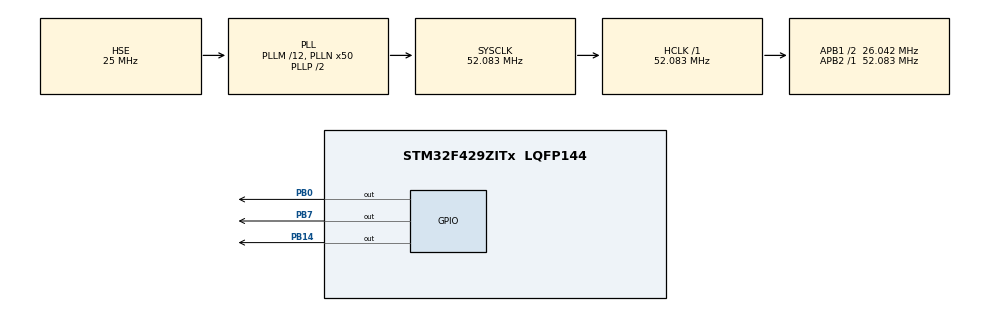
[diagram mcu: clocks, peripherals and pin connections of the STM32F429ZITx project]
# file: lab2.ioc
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FREERTOS.Tasks01=defaultTask,24,128,StartDefaultTask,Default,NULL,Dynamic,NULL,NULL;LED1,8,128,StartTask02,Default,NULL,Dynamic,NULL,NULL;LED2,8,128,StartTask03,Default,NULL,Dynamic,NULL,NULL;LED3,8,128,StartTask04,Default,NULL,Dynamic,NULL,NULL
Mcu.Family=STM32F4
Mcu.Name=STM32F429ZITx
Mcu.Package=LQFP144
NVIC.PriorityGroup=NVIC_PRIORITYGROUP_4
NVIC.TIM1_UP_TIM10_IRQn=true\:0\:0\:false\:false\:true\:false\:false\:true
NVIC.TimeBase=TIM1_UP_TIM10_IRQn
NVIC.TimeBaseIP=TIM1
PB0.Signal=GPIO_Output
PB14.Signal=GPIO_Output
PB7.Signal=GPIO_Output
PH0/OSC_IN.Mode=HSE-External-Oscillator
PH0/OSC_IN.Signal=RCC_OSC_IN
PH1/OSC_OUT.Mode=HSE-External-Oscillator
PH1/OSC_OUT.Signal=RCC_OSC_OUT
ProjectManager.HeapSize=0x200
ProjectManager.StackSize=0x400
ProjectManager.TargetToolchain=STM32CubeIDE
RCC.48MHZClocksFreq_Value=26041666.666666664
RCC.AHBFreq_Value=52083333.33333333
RCC.APB1CLKDivider=RCC_HCLK_DIV2
RCC.APB1Freq_Value=26041666.666666664
RCC.APB1TimFreq_Value=52083333.33333333
RCC.APB2Freq_Value=52083333.33333333
RCC.APB2TimFreq_Value=52083333.33333333
RCC.CortexFreq_Value=52083333.33333333
RCC.HCLKFreq_Value=52083333.33333333
RCC.HSE_VALUE=25000000
RCC.HSI_VALUE=16000000
RCC.LSE_VALUE=32768
RCC.PLLM=12
RCC.PLLN=50
RCC.PLLSourceVirtual=RCC_PLLSOURCE_HSE
RCC.SYSCLKFreq_VALUE=52083333.33333333
RCC.SYSCLKSource=RCC_SYSCLKSOURCE_PLLCLK
RCC.VCOOutputFreq_Value=104166666.66666666
VP_FREERTOS_VS_CMSIS_V2.Mode=CMSIS_V2
VP_SYS_VS_tim1.Mode=TIM1
board=custom

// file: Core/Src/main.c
/* USER CODE BEGIN Header */
/**
  ******************************************************************************
  * @file           : main.c
  * @brief          : Main program body
  ******************************************************************************
  * @attention
  *
  * <h2><center>&copy; Copyright (c) 2020 STMicroelectronics.
  * All rights reserved.</center></h2>
  *
  * This software component is licensed by ST under BSD 3-Clause license,
  * the "License"; You may not use this file except in compliance with the
  * License. You may obtain a copy of the License at:
  *                        opensource.org/licenses/BSD-3-Clause
  *
  ******************************************************************************
  */
/* USER CODE END Header */

#include "main.h"
#include "cmsis_os.h"

/* Definitions for defaultTask */
osThreadId_t defaultTaskHandle;
const osThreadAttr_t defaultTask_attributes = {
  .name = "defaultTask",
  .priority = (osPriority_t) osPriorityNormal,
  .stack_size = 128 * 4
};
/* Definitions for LED1 */
osThreadId_t LED1Handle;
const osThreadAttr_t LED1_attributes = {
  .name = "LED1",
  .priority = (osPriority_t) osPriorityLow,
  .stack_size = 128 * 4
};
/* Definitions for LED2 */
osThreadId_t LED2Handle;
const osThreadAttr_t LED2_attributes = {
  .name = "LED2",
  .priority = (osPriority_t) osPriorityLow,
  .stack_size = 128 * 4
};
/* Definitions for LED3 */
osThreadId_t LED3Handle;
const osThreadAttr_t LED3_attributes = {
  .name = "LED3",
  .priority = (osPriority_t) osPriorityLow,
  .stack_size = 128 * 4
};

void SystemClock_Config(void);
static void MX_GPIO_Init(void);
void StartDefaultTask(void *argument);
void StartTask02(void *argument);
void StartTask03(void *argument);
void StartTask04(void *argument);

int main(void)
{

  /* MCU Configuration--------------------------------------------------------*/

  /* Reset of all peripherals, Initializes the Flash interface and the Systick. */
  HAL_Init();

  /* Configure the system clock */
  SystemClock_Config();

  /* Initialize all configured peripherals */
  MX_GPIO_Init();

  /* Init scheduler */
  osKernelInitialize();

  /* Create the thread(s) */
  /* creation of defaultTask */
  defaultTaskHandle = osThreadNew(StartDefaultTask, NULL, &defaultTask_attributes);

  /* creation of LED1 */
  LED1Handle = osThreadNew(StartTask02, NULL, &LED1_attributes);

  /* creation of LED2 */
  LED2Handle = osThreadNew(StartTask03, NULL, &LED2_attributes);

  /* creation of LED3 */
  LED3Handle = osThreadNew(StartTask04, NULL, &LED3_attributes);

  /* Start scheduler */
  osKernelStart();

  /* We should never get here as control is now taken by the scheduler */
  /* Infinite loop */
  while (1)
  {

  }
}

void SystemClock_Config(void)
{
  RCC_OscInitTypeDef RCC_OscInitStruct = {0};
  RCC_ClkInitTypeDef RCC_ClkInitStruct = {0};

  /** Configure the main internal regulator output voltage
  */
  __HAL_RCC_PWR_CLK_ENABLE();
  __HAL_PWR_VOLTAGESCALING_CONFIG(PWR_REGULATOR_VOLTAGE_SCALE3);
  /** Initializes the CPU, AHB and APB busses clocks
  */
  RCC_OscInitStruct.OscillatorType = RCC_OSCILLATORTYPE_HSE;
  RCC_OscInitStruct.HSEState = RCC_HSE_ON;
  RCC_OscInitStruct.PLL.PLLState = RCC_PLL_ON;
  RCC_OscInitStruct.PLL.PLLSource = RCC_PLLSOURCE_HSE;
  RCC_OscInitStruct.PLL.PLLM = 12;
  RCC_OscInitStruct.PLL.PLLN = 50;
  RCC_OscInitStruct.PLL.PLLP = RCC_PLLP_DIV2;
  RCC_OscInitStruct.PLL.PLLQ = 4;
  if (HAL_RCC_OscConfig(&RCC_OscInitStruct) != HAL_OK)
  {
    Error_Handler();
  }
  /** Initializes the CPU, AHB and APB busses clocks
  */
  RCC_ClkInitStruct.ClockType = RCC_CLOCKTYPE_HCLK|RCC_CLOCKTYPE_SYSCLK
                              |RCC_CLOCKTYPE_PCLK1|RCC_CLOCKTYPE_PCLK2;
  RCC_ClkInitStruct.SYSCLKSource = RCC_SYSCLKSOURCE_PLLCLK;
  RCC_ClkInitStruct.AHBCLKDivider = RCC_SYSCLK_DIV1;
  RCC_ClkInitStruct.APB1CLKDivider = RCC_HCLK_DIV2;
  RCC_ClkInitStruct.APB2CLKDivider = RCC_HCLK_DIV1;

  if (HAL_RCC_ClockConfig(&RCC_ClkInitStruct, FLASH_LATENCY_1) != HAL_OK)
  {
    Error_Handler();
  }
}

static void MX_GPIO_Init(void)
{
  GPIO_InitTypeDef GPIO_InitStruct = {0};

  /* GPIO Ports Clock Enable */
  __HAL_RCC_GPIOH_CLK_ENABLE();
  __HAL_RCC_GPIOB_CLK_ENABLE();

  /*Configure GPIO pin Output Level */
  HAL_GPIO_WritePin(GPIOB, GPIO_PIN_0|GPIO_PIN_14|GPIO_PIN_7, GPIO_PIN_RESET);

  /*Configure GPIO pins : PB0 PB14 PB7 */
  GPIO_InitStruct.Pin = GPIO_PIN_0|GPIO_PIN_14|GPIO_PIN_7;
  GPIO_InitStruct.Mode = GPIO_MODE_OUTPUT_PP;
  GPIO_InitStruct.Pull = GPIO_NOPULL;
  GPIO_InitStruct.Speed = GPIO_SPEED_FREQ_LOW;
  HAL_GPIO_Init(GPIOB, &GPIO_InitStruct);

}

void StartDefaultTask(void *argument)
{
  for(;;)
  {
    osDelay(1);
  }
}

void StartTask02(void *argument)
{
  /* USER CODE BEGIN StartTask02 */
  /* Infinite loop */
  for(;;)
  {
	  HAL_GPIO_TogglePin(GPIOB, GPIO_PIN_0);
	  HAL_Delay(250);
//    osDelay(1);
  }
  /* USER CODE END StartTask02 */
}

void StartTask03(void *argument)
{
  /* USER CODE BEGIN StartTask03 */
  /* Infinite loop */
  for(;;)
  {
	  HAL_GPIO_TogglePin(GPIOB, GPIO_PIN_7);
	  HAL_Delay(500);
//    osDelay(1);
  }
  /* USER CODE END StartTask03 */
}

void StartTask04(void *argument)
{
  /* USER CODE BEGIN StartTask04 */
  /* Infinite loop */
  for(;;)
  {
	  HAL_GPIO_TogglePin(GPIOB, GPIO_PIN_14);
	  HAL_Delay(750);
//    osDelay(1);
  }
  /* USER CODE END StartTask04 */
}

 /**
  * @brief  Period elapsed callback in non blocking mode
  * @note   This function is called  when TIM1 interrupt took place, inside
  * HAL_TIM_IRQHandler(). It makes a direct call to HAL_IncTick() to increment
  * a global variable "uwTick" used as application time base.
  * @param  htim : TIM handle
  * @retval None
  */
void HAL_TIM_PeriodElapsedCallback(TIM_HandleTypeDef *htim)
{
  if (htim->Instance == TIM1) {
    HAL_IncTick();
  }
}

void Error_Handler(void)
{
}

/************************ (C) COPYRIGHT STMicroelectronics *****END OF FILE****/
